# NANO100AN_v1 register map
File version: 1.0
Registers are 32-bit, read-write, reset 0x0 unless marked. A register's access mark holds for its fields unless they carry their own. Offsets are from the block's base; [hi:lo] are bit positions.

## PDMA_CH1 — VDMA Register Map
Base 0x50008100
Same registers: PDMA_CH2 0x50008200, PDMA_CH3 0x50008300, PDMA_CH4 0x50008400
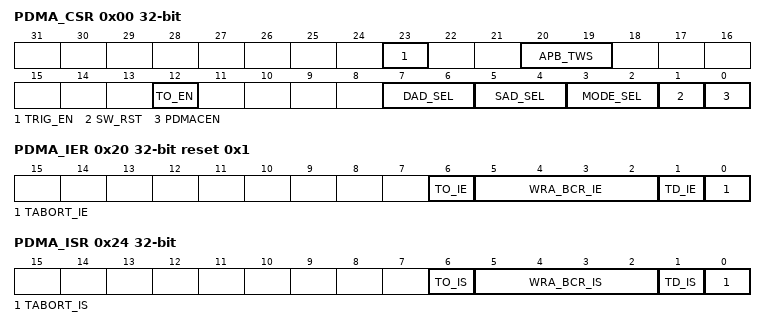
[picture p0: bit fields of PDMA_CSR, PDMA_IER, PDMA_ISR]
0x00 PDMA_CSR — PDMA Control Register
  [23] TRIG_EN — Trigger Enable Control. Note: When PDMA transfer completed, this bit will be cleared automatically. If the bus error occurs, all PDMA transfer will be stopped. User must reset all PDMA channel, and then trigger again.
    0=No effect; 1=PDMA data read or write transfer Enabled
  [20:19] APB_TWS — Peripheral Transfer Width Selection. Note: This field is meaningful only when MODE_SEL is Peripheral to Memory mode (Peripheral-to-Memory) or Memory to Peripheral mode (Memory-to-Peripheral).
    0=One word (32-bit) is transferred for every PDMA operation; 1=One byte (8-bit) is transferred for every PDMA operation; 2=One half-word (16-bit) is transferred for every PDMA operation
  [12] TO_EN — Time-Out Enable Control. This bit will enable PDMA internal Counter. While this counter counts to zero, the TO_IS will be set.
    0=PDMA internal counter Disabled; 1=PDMA internal counter Enabled
  [7:6] DAD_SEL — Transfer Destination Address Direction Selection
    0=Transfer Destination address is incremented successively; 2=Transfer Destination address is fixed (This feature can be used when data where transferred from multiple sources to a single destination); 3=Transfer Destination address is wrapped around (When the PDMA_CBCR is equal to 0, the PDMA_CDAR and PDMA_CBCR register will be updated by PDMA_DAR and PDMA_BCR automatically. PDMA will start another transfer without user trigger until PDMA_EN disabled. When the PDMA_EN is disabled, the PDMA will complete the active transfer but the remained data which in the PDMA_BUF will not transfer to destination address)
  [5:4] SAD_SEL — Transfer Source Address Direction Selection
    0=Transfer Source address is incremented successively; 2=Transfer Source address is fixed (This feature can be used when data where transferred from a single source to multiple destinations); 3=Transfer Source address is wrap around (When the PDMA_CBCR is equal to 0, the PDMA_CSAR and PDMA_CBCR register will be updated by PDMA_SAR and PDMA_BCR automatically. PDMA will start another transfer without user trigger until PDMA_EN disabled. When the PDMA_EN is disabled, the PDMA will complete the active transfer but the remained data which in the PDMA_BUF will not transfer to destination address)
  [3:2] MODE_SEL — PDMA Mode Selection
    0=Memory to Memory mode (Memory-to-Memory); 1=Peripheral to Memory mode (Peripheral-to-Memory); 2=Memory to Peripheral mode (Memory-to-Peripheral)
  [1] SW_RST — Software Engine Reset
    0=No effect; 1=Reset the internal state machine and pointers. The contents of control register will not be cleared. This bit will be automatically cleared after few clock cycles
  [0] PDMACEN — PDMA Channel Enable Control. Setting this bit to "1" enables PDMA operation. If this bit is cleared, PDMA will ignore all PDMA request and force Bus Master into IDLE state.
0x04 PDMA_SAR — PDMA Source Address Register
  [31:0] PDMA_SAR — PDMA Transfer Source Address Bits. This field indicates a 32-bit source address of PDMA. Note: The source address must be word alignment.
0x08 PDMA_DAR — PDMA Destination Address Register
  [31:0] PDMA_DAR — PDMA Transfer Destination Address Bits. This field indicates a 32-bit destination address of PDMA. Note : The destination address must be word alignment
0x0C PDMA_BCR — PDMA Transfer Byte Count Register
  [15:0] PDMA_BCR — PDMA Transfer Byte Count Bits. This field indicates a 16-bit transfer byte count of PDMA.
0x14 PDMA_CSAR ro — PDMA Current Source Address Register
  [31:0] PDMA_CSAR — PDMA Current Source Address Bits (Read Only). This field indicates the source address where the PDMA transfer just occurred.
0x18 PDMA_CDAR ro — PDMA Current Destination Address Register
  [31:0] PDMA_CDAR — PDMA Current Destination Address Bits (Read Only). This field indicates the destination address where the PDMA transfer just occurred.
0x1C PDMA_CBCR ro — PDMA Current Transfer Byte Count Register
  [23:0] PDMA_CBCR — PDMA Current Byte Count Bits (Read Only). This field indicates the current remained byte count of PDMA. Note: This field will be changed when PDMA finishes data transfer (data transfer to destination address).
0x20 PDMA_IER reset 0x1 — PDMA Interrupt Enable Register
  [6] TO_IE — Time-Out Interrupt Enable Control
    0=Time-out interrupt Disabled; 1=Time-out interrupt Enabled
  [5:2] WRA_BCR_IE — Wrap Around Byte Count Interrupt Enable Control
    1=Interrupt enable of PDMA_CBCR equals 0; 4=Interrupt enable of PDMA_CBCR equals 1/2 PDMA_BCR
  [1] TD_IE — PDMA Transfer Done Interrupt Enable Control
    0=Interrupt generator Disabled when PDMA transfer is done; 1=Interrupt generator Enabled when PDMA transfer is done
  [0] TABORT_IE — PDMA Read/Write Target Abort Interrupt Enable Control
    0=Target abort interrupt generation Disabled during PDMA transfer; 1=Target abort interrupt generation Enabled during PDMA transfer
0x24 PDMA_ISR — PDMA Interrupt Status Register
  [6] TO_IS — Time-Out Interrupt Status Flag. This flag indicated that PDMA has waited peripheral request for a period defined by PDMA_TCR. Note: This bit is cleared by writing "1" to it.
    0=No time-out flag; 1=Time-out flag
  [5:2] WRA_BCR_IS — Wrap Around Transfer Byte Count Interrupt Status Flag
  [1] TD_IS — Transfer Done Interrupt Status Flag. This bit indicates that PDMA has finished all transfer. Note: This bit is cleared by writing "1" to it.
    0=Not finished yet; 1=Done
  [0] TABORT_IS — PDMA Read/Write Target Abort Interrupt Status Flag. Note1: This bit is cleared by writing "1" to it. Note2: This bit indicates bus master received ERROR response or not, if bus master received occur it means that target abort is happened. PDMA controller will stop transfer and respond this event to user then go to IDLE state. When target abort occurred, user must reset PDMA controller, and then transfer those data again.
    0=No bus ERROR response received; 1=Bus ERROR response received
0x28 PDMA_TCR — PDMA Timer Counter Setting Register
  [15:0] PDMA_TCR — PDMA Timer Count Setting Bits. Each PDMA channel contains an internal counter. This internal counter will reload and start counting when completing each peripheral request service. The internal counter loads the value of PDAM_TCR and starts counting down when setting TO_EN (PDMA_CSRx[12]). PDMA will request interrupt when this internal counter reaches 0 and TO_IE (PDMA_IERx[6]) is 1.
0x80 PDMA_BUF ro — PDMA Internal Buffer FIFO
  [31:0] PDMA_BUF — PDMA Internal Buffer FIFO (Read Only). Each channel has its own 1 word internal buffer.
